# ATmega2560 device description
Architecture: AVR8; Family: megaAVR
Registers are 8-bit, access not given, no defined reset value unless marked. A register's access mark holds for its fields unless they carry their own. Offsets are from the block's base; [hi:lo] are bit positions.

## USART2 — USART
Instances: USART2 0x00
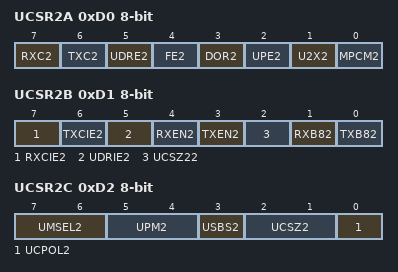
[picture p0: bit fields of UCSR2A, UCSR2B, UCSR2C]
0xD0 UCSR2A — USART Control and Status Register A
  [7] RXC2 — USART Receive Complete
  [6] TXC2 — USART Transmitt Complete
  [5] UDRE2 — USART Data Register Empty
  [4] FE2 — Framing Error
  [3] DOR2 — Data overRun
  [2] UPE2 — Parity Error
  [1] U2X2 — Double the USART transmission speed
  [0] MPCM2 — Multi-processor Communication Mode
0xD1 UCSR2B — USART Control and Status Register B
  [7] RXCIE2 — RX Complete Interrupt Enable
  [6] TXCIE2 — TX Complete Interrupt Enable
  [5] UDRIE2 — USART Data register Empty Interrupt Enable
  [4] RXEN2 — Receiver Enable
  [3] TXEN2 — Transmitter Enable
  [2] UCSZ22 — Character Size
  [1] RXB82 — Receive Data Bit 8
  [0] TXB82 — Transmit Data Bit 8
0xD2 UCSR2C — USART Control and Status Register C
  [7:6] UMSEL2 — USART Mode Select
    0=Asynchronous USART; 1=Synchronous USART; 3=Master SPI
  [5:4] UPM2 — Parity Mode Bits
    0=Disabled; 2=Enabled, Even Parity; 3=Enabled, Odd Parity
  [3] USBS2 — Stop Bit Select
    0=1-bit; 1=2-bit
  [2:1] UCSZ2 — Character Size
  [0] UCPOL2 — Clock Polarity
0xD4 UBRR2 16-bit bits used 11:0 — USART Baud Rate Register Bytes
0xD6 UDR2 — USART I/O Data Register

## USART3 — USART
Instances: USART3 0x00
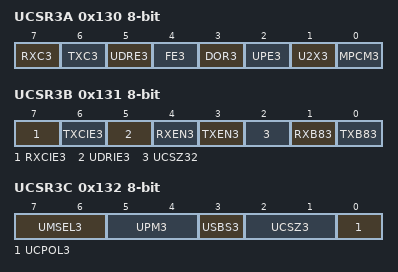
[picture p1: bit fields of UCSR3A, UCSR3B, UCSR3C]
0x130 UCSR3A — USART Control and Status Register A
  [7] RXC3 — USART Receive Complete
  [6] TXC3 — USART Transmitt Complete
  [5] UDRE3 — USART Data Register Empty
  [4] FE3 — Framing Error
  [3] DOR3 — Data overRun
  [2] UPE3 — Parity Error
  [1] U2X3 — Double the USART transmission speed
  [0] MPCM3 — Multi-processor Communication Mode
0x131 UCSR3B — USART Control and Status Register B
  [7] RXCIE3 — RX Complete Interrupt Enable
  [6] TXCIE3 — TX Complete Interrupt Enable
  [5] UDRIE3 — USART Data register Empty Interrupt Enable
  [4] RXEN3 — Receiver Enable
  [3] TXEN3 — Transmitter Enable
  [2] UCSZ32 — Character Size
  [1] RXB83 — Receive Data Bit 8
  [0] TXB83 — Transmit Data Bit 8
0x132 UCSR3C — USART Control and Status Register C
  [7:6] UMSEL3 — USART Mode Select
    0=Asynchronous USART; 1=Synchronous USART; 3=Master SPI
  [5:4] UPM3 — Parity Mode Bits
    0=Disabled; 2=Enabled, Even Parity; 3=Enabled, Odd Parity
  [3] USBS3 — Stop Bit Select
    0=1-bit; 1=2-bit
  [2:1] UCSZ3 — Character Size
  [0] UCPOL3 — Clock Polarity
0x134 UBRR3 16-bit bits used 11:0 — USART Baud Rate Register Bytes
0x136 UDR3 — USART I/O Data Register

## TWI — Two Wire Serial Interface
Instances: TWI 0x00
0xB8 TWBR — TWI Bit Rate register
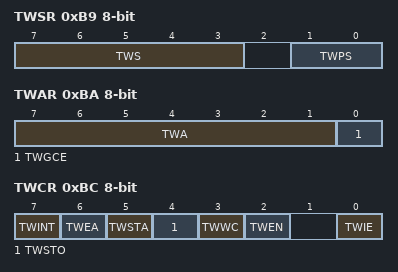
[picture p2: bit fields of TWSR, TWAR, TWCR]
0xB9 TWSR — TWI Status Register
  [7:3] TWS (bit 3 of the value upward) — TWI Status
  [1:0] TWPS — TWI Prescaler
    0=1; 1=4; 2=16; 3=64
0xBA TWAR — TWI (Slave) Address register
  [7:1] TWA — TWI (Slave) Address register Bits
  [0] TWGCE — TWI General Call Recognition Enable Bit
0xBB TWDR — TWI Data register
0xBC TWCR — TWI Control Register
  [7] TWINT — TWI Interrupt Flag
  [6] TWEA — TWI Enable Acknowledge Bit
  [5] TWSTA — TWI Start Condition Bit
  [4] TWSTO — TWI Stop Condition Bit
  [3] TWWC — TWI Write Collition Flag
  [2] TWEN — TWI Enable Bit
  [0] TWIE — TWI Interrupt Enable
0xBD TWAMR — TWI (Slave) Address Mask Register
  [7:1] TWAM

## SPI — Serial Peripheral Interface
Instances: SPI 0x00
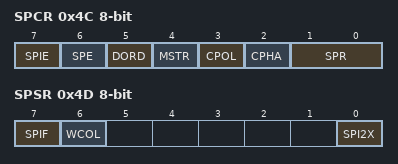
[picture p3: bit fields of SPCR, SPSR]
0x4C SPCR — SPI Control Register
  [7] SPIE — SPI Interrupt Enable
  [6] SPE — SPI Enable
  [5] DORD — Data Order
  [4] MSTR — Master/Slave Select
  [3] CPOL — Clock polarity
  [2] CPHA — Clock Phase
  [1:0] SPR — SPI Clock Rate Selects
    0=fosc/4; 1=fosc/16; 2=fosc/64; 3=fosc/128; 4=fosc/2; 5=fosc/8; 6=fosc/32; 7=fosc/64
0x4D SPSR — SPI Status Register
  [7] SPIF — SPI Interrupt Flag
  [6] WCOL — Write Collision Flag
  [0] SPI2X — Double SPI Speed Bit
0x4E SPDR — SPI Data Register
